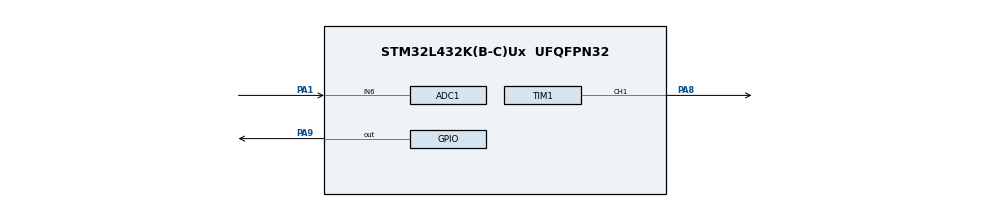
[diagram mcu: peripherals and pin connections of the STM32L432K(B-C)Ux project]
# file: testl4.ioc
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ADC1.Channel-0\#ChannelRegularConversion=ADC_CHANNEL_6
ADC1.ContinuousConvMode=ENABLE
ADC1.NbrOfConversionFlag=1
ADC1.OffsetNumber-0\#ChannelRegularConversion=ADC_OFFSET_NONE
ADC1.Overrun=ADC_OVR_DATA_OVERWRITTEN
ADC1.Rank-0\#ChannelRegularConversion=1
ADC1.SamplingTime-0\#ChannelRegularConversion=ADC_SAMPLETIME_2CYCLES_5
ADC1.master=1
Mcu.Family=STM32L4
Mcu.Name=STM32L432K(B-C)Ux
Mcu.Package=UFQFPN32
NVIC.ADC1_IRQn=true\:0\:0\:false\:false\:true\:true
NVIC.PriorityGroup=NVIC_PRIORITYGROUP_4
NVIC.TIM1_CC_IRQn=true\:0\:0\:false\:false\:true\:true
PA1.Signal=SharedAnalog_PA1
PA8.GPIO_Speed=GPIO_SPEED_FREQ_VERY_HIGH
PA8.Signal=S_TIM1_CH1
PA9.PinState=GPIO_PIN_SET
PA9.Signal=GPIO_Output
ProjectManager.HeapSize=0x200
ProjectManager.StackSize=0x400
ProjectManager.TargetToolchain=SW4STM32
RCC.ADCFreq_Value=32000000
RCC.HSE_VALUE=8000000
RCC.HSI48_VALUE=48000000
RCC.HSI_VALUE=16000000
RCC.LSE_VALUE=32768
RCC.MSI_VALUE=4000000
RCC.PLLSAI1N=16
RCC.USBFreq_Value=32000000
RCC.VCOOutputFreq_Value=32000000
SH.S_TIM1_CH1.0=TIM1_CH1,PWM Generation1 CH1
SH.SharedAnalog_PA1.0=COMP1_INP
SH.SharedAnalog_PA1.1=ADC1_IN6,IN6-Single-Ended
TIM1.AutoReloadPreload=TIM_AUTORELOAD_PRELOAD_ENABLE
TIM1.Channel-PWM\ Generation1\ CH1=TIM_CHANNEL_1
TIM1.OCMode_PWM-PWM\ Generation1\ CH1=TIM_OCMODE_PWM2
TIM1.Period=100
TIM1.Prescaler=40
TIM1.Pulse-PWM\ Generation1\ CH1=50
VP_TIM1_VS_ClockSourceINT.Mode=Internal
board=testl4

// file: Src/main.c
/**
  ******************************************************************************
  * File Name          : main.c
  * Description        : Main program body
  ******************************************************************************
  ** This notice applies to any and all portions of this file
  * that are not between comment pairs USER CODE BEGIN and
  * USER CODE END. Other portions of this file, whether
  * inserted by the user or by software development tools
  * are owned by their respective copyright owners.
  *
  * COPYRIGHT(c) 2017 STMicroelectronics
  *
  * Redistribution and use in source and binary forms, with or without modification,
  * are permitted provided that the following conditions are met:
  *   1. Redistributions of source code must retain the above copyright notice,
  *      this list of conditions and the following disclaimer.
  *   2. Redistributions in binary form must reproduce the above copyright notice,
  *      this list of conditions and the following disclaimer in the documentation
  *      and/or other materials provided with the distribution.
  *   3. Neither the name of STMicroelectronics nor the names of its contributors
  *      may be used to endorse or promote products derived from this software
  *      without specific prior written permission.
  *
  * THIS SOFTWARE IS PROVIDED BY THE COPYRIGHT HOLDERS AND CONTRIBUTORS "AS IS"
  * AND ANY EXPRESS OR IMPLIED WARRANTIES, INCLUDING, BUT NOT LIMITED TO, THE
  * IMPLIED WARRANTIES OF MERCHANTABILITY AND FITNESS FOR A PARTICULAR PURPOSE ARE
  * DISCLAIMED. IN NO EVENT SHALL THE COPYRIGHT HOLDER OR CONTRIBUTORS BE LIABLE
  * FOR ANY DIRECT, INDIRECT, INCIDENTAL, SPECIAL, EXEMPLARY, OR CONSEQUENTIAL
  * DAMAGES (INCLUDING, BUT NOT LIMITED TO, PROCUREMENT OF SUBSTITUTE GOODS OR
  * SERVICES; LOSS OF USE, DATA, OR PROFITS; OR BUSINESS INTERRUPTION) HOWEVER
  * CAUSED AND ON ANY THEORY OF LIABILITY, WHETHER IN CONTRACT, STRICT LIABILITY,
  * OR TORT (INCLUDING NEGLIGENCE OR OTHERWISE) ARISING IN ANY WAY OUT OF THE USE
  * OF THIS SOFTWARE, EVEN IF ADVISED OF THE POSSIBILITY OF SUCH DAMAGE.
  *
  ******************************************************************************
  */
#include "main.h"
#include "stm32l4xx_hal.h"

ADC_HandleTypeDef hadc1;

TIM_HandleTypeDef htim1;

/* USER CODE BEGIN PV */
/* Private variables ---------------------------------------------------------*/

/* USER CODE END PV */

void SystemClock_Config(void);
static void MX_GPIO_Init(void);
static void MX_TIM1_Init(void);
static void MX_ADC1_Init(void);

void HAL_TIM_MspPostInit(TIM_HandleTypeDef *htim);

/* USER CODE BEGIN PFP */
/* Private function prototypes -----------------------------------------------*/

/* USER CODE END PFP */

int main(void)
{

  /* MCU Configuration----------------------------------------------------------*/

  /* Reset of all peripherals, Initializes the Flash interface and the Systick. */
  HAL_Init();

  /* Configure the system clock */
  SystemClock_Config();

  /* USER CODE BEGIN SysInit */
  uint8_t egr_val;
  /* USER CODE END SysInit */

  /* Initialize all configured peripherals */
  MX_GPIO_Init();
  MX_TIM1_Init();
  MX_ADC1_Init();

  /* USER CODE BEGIN 2 */
  //HAL_ADC_Start_IT(&hadc1);
  HAL_TIM_PWM_Start(&htim1,TIM_CHANNEL_1);
  //HAL_TIM_PWM_Start(&htim1,TIM_CHANNEL_2);
  int i = 0;
  /* USER CODE END 2 */

  /* Infinite loop */
  /* USER CODE BEGIN WHILE */
  while (1)
  {
	  //egr_val = *egr;
	  printf("egr: ");
  /* USER CODE END WHILE */

  }

}

/** System Clock Configuration
*/
void SystemClock_Config(void)
{

  RCC_OscInitTypeDef RCC_OscInitStruct;
  RCC_ClkInitTypeDef RCC_ClkInitStruct;
  RCC_PeriphCLKInitTypeDef PeriphClkInit;

    /**Initializes the CPU, AHB and APB busses clocks
    */
  RCC_OscInitStruct.OscillatorType = RCC_OSCILLATORTYPE_MSI;
  RCC_OscInitStruct.MSIState = RCC_MSI_ON;
  RCC_OscInitStruct.MSICalibrationValue = 0;
  RCC_OscInitStruct.MSIClockRange = RCC_MSIRANGE_6;
  RCC_OscInitStruct.PLL.PLLState = RCC_PLL_NONE;
  if (HAL_RCC_OscConfig(&RCC_OscInitStruct) != HAL_OK)
  {
    _Error_Handler(__FILE__, __LINE__);
  }

    /**Initializes the CPU, AHB and APB busses clocks
    */
  RCC_ClkInitStruct.ClockType = RCC_CLOCKTYPE_HCLK|RCC_CLOCKTYPE_SYSCLK
                              |RCC_CLOCKTYPE_PCLK1|RCC_CLOCKTYPE_PCLK2;
  RCC_ClkInitStruct.SYSCLKSource = RCC_SYSCLKSOURCE_MSI;
  RCC_ClkInitStruct.AHBCLKDivider = RCC_SYSCLK_DIV1;
  RCC_ClkInitStruct.APB1CLKDivider = RCC_HCLK_DIV1;
  RCC_ClkInitStruct.APB2CLKDivider = RCC_HCLK_DIV1;

  if (HAL_RCC_ClockConfig(&RCC_ClkInitStruct, FLASH_LATENCY_0) != HAL_OK)
  {
    _Error_Handler(__FILE__, __LINE__);
  }

  PeriphClkInit.PeriphClockSelection = RCC_PERIPHCLK_ADC;
  PeriphClkInit.AdcClockSelection = RCC_ADCCLKSOURCE_PLLSAI1;
  PeriphClkInit.PLLSAI1.PLLSAI1Source = RCC_PLLSOURCE_MSI;
  PeriphClkInit.PLLSAI1.PLLSAI1M = 1;
  PeriphClkInit.PLLSAI1.PLLSAI1N = 16;
  PeriphClkInit.PLLSAI1.PLLSAI1P = RCC_PLLP_DIV7;
  PeriphClkInit.PLLSAI1.PLLSAI1Q = RCC_PLLQ_DIV2;
  PeriphClkInit.PLLSAI1.PLLSAI1R = RCC_PLLR_DIV2;
  PeriphClkInit.PLLSAI1.PLLSAI1ClockOut = RCC_PLLSAI1_ADC1CLK;
  if (HAL_RCCEx_PeriphCLKConfig(&PeriphClkInit) != HAL_OK)
  {
    _Error_Handler(__FILE__, __LINE__);
  }

    /**Configure the main internal regulator output voltage
    */
  if (HAL_PWREx_ControlVoltageScaling(PWR_REGULATOR_VOLTAGE_SCALE1) != HAL_OK)
  {
    _Error_Handler(__FILE__, __LINE__);
  }

    /**Configure the Systick interrupt time
    */
  HAL_SYSTICK_Config(HAL_RCC_GetHCLKFreq()/1000);

    /**Configure the Systick
    */
  HAL_SYSTICK_CLKSourceConfig(SYSTICK_CLKSOURCE_HCLK);

  /* SysTick_IRQn interrupt configuration */
  HAL_NVIC_SetPriority(SysTick_IRQn, 0, 0);
}

/* ADC1 init function */
static void MX_ADC1_Init(void)
{

  ADC_ChannelConfTypeDef sConfig;

    /**Common config
    */
  hadc1.Instance = ADC1;
  hadc1.Init.ClockPrescaler = ADC_CLOCK_ASYNC_DIV1;
  hadc1.Init.Resolution = ADC_RESOLUTION_12B;
  hadc1.Init.DataAlign = ADC_DATAALIGN_RIGHT;
  hadc1.Init.ScanConvMode = ADC_SCAN_DISABLE;
  hadc1.Init.EOCSelection = ADC_EOC_SINGLE_CONV;
  hadc1.Init.LowPowerAutoWait = DISABLE;
  hadc1.Init.ContinuousConvMode = ENABLE;
  hadc1.Init.NbrOfConversion = 1;
  hadc1.Init.DiscontinuousConvMode = DISABLE;
  hadc1.Init.NbrOfDiscConversion = 1;
  hadc1.Init.ExternalTrigConv = ADC_SOFTWARE_START;
  hadc1.Init.ExternalTrigConvEdge = ADC_EXTERNALTRIGCONVEDGE_NONE;
  hadc1.Init.DMAContinuousRequests = DISABLE;
  hadc1.Init.Overrun = ADC_OVR_DATA_OVERWRITTEN;
  hadc1.Init.OversamplingMode = DISABLE;
  if (HAL_ADC_Init(&hadc1) != HAL_OK)
  {
    _Error_Handler(__FILE__, __LINE__);
  }

    /**Configure Regular Channel
    */
  sConfig.Channel = ADC_CHANNEL_6;
  sConfig.Rank = 1;
  sConfig.SamplingTime = ADC_SAMPLETIME_2CYCLES_5;
  sConfig.SingleDiff = ADC_SINGLE_ENDED;
  sConfig.OffsetNumber = ADC_OFFSET_NONE;
  sConfig.Offset = 0;
  if (HAL_ADC_ConfigChannel(&hadc1, &sConfig) != HAL_OK)
  {
    _Error_Handler(__FILE__, __LINE__);
  }

}

/* TIM1 init function */
static void MX_TIM1_Init(void)
{

  TIM_ClockConfigTypeDef sClockSourceConfig;
  TIM_MasterConfigTypeDef sMasterConfig;
  TIM_OC_InitTypeDef sConfigOC;
  TIM_BreakDeadTimeConfigTypeDef sBreakDeadTimeConfig;

  htim1.Instance = TIM1;
  htim1.Init.Prescaler = 40;
  htim1.Init.CounterMode = TIM_COUNTERMODE_UP;
  htim1.Init.Period = 100;
  htim1.Init.ClockDivision = TIM_CLOCKDIVISION_DIV1;
  htim1.Init.RepetitionCounter = 0;
  htim1.Init.AutoReloadPreload = TIM_AUTORELOAD_PRELOAD_ENABLE;
  if (HAL_TIM_Base_Init(&htim1) != HAL_OK)
  {
    _Error_Handler(__FILE__, __LINE__);
  }

  sClockSourceConfig.ClockSource = TIM_CLOCKSOURCE_INTERNAL;
  if (HAL_TIM_ConfigClockSource(&htim1, &sClockSourceConfig) != HAL_OK)
  {
    _Error_Handler(__FILE__, __LINE__);
  }

  if (HAL_TIM_PWM_Init(&htim1) != HAL_OK)
  {
    _Error_Handler(__FILE__, __LINE__);
  }

  sMasterConfig.MasterOutputTrigger = TIM_TRGO_RESET;
  sMasterConfig.MasterOutputTrigger2 = TIM_TRGO2_RESET;
  sMasterConfig.MasterSlaveMode = TIM_MASTERSLAVEMODE_DISABLE;
  if (HAL_TIMEx_MasterConfigSynchronization(&htim1, &sMasterConfig) != HAL_OK)
  {
    _Error_Handler(__FILE__, __LINE__);
  }

  sConfigOC.OCMode = TIM_OCMODE_PWM2;
  sConfigOC.Pulse = 50;
  sConfigOC.OCPolarity = TIM_OCPOLARITY_HIGH;
  sConfigOC.OCNPolarity = TIM_OCNPOLARITY_HIGH;
  sConfigOC.OCFastMode = TIM_OCFAST_DISABLE;
  sConfigOC.OCIdleState = TIM_OCIDLESTATE_RESET;
  sConfigOC.OCNIdleState = TIM_OCNIDLESTATE_RESET;
  if (HAL_TIM_PWM_ConfigChannel(&htim1, &sConfigOC, TIM_CHANNEL_1) != HAL_OK)
  {
    _Error_Handler(__FILE__, __LINE__);
  }

  sBreakDeadTimeConfig.OffStateRunMode = TIM_OSSR_DISABLE;
  sBreakDeadTimeConfig.OffStateIDLEMode = TIM_OSSI_DISABLE;
  sBreakDeadTimeConfig.LockLevel = TIM_LOCKLEVEL_OFF;
  sBreakDeadTimeConfig.DeadTime = 0;
  sBreakDeadTimeConfig.BreakState = TIM_BREAK_DISABLE;
  sBreakDeadTimeConfig.BreakPolarity = TIM_BREAKPOLARITY_HIGH;
  sBreakDeadTimeConfig.BreakFilter = 0;
  sBreakDeadTimeConfig.Break2State = TIM_BREAK2_DISABLE;
  sBreakDeadTimeConfig.Break2Polarity = TIM_BREAK2POLARITY_HIGH;
  sBreakDeadTimeConfig.Break2Filter = 0;
  sBreakDeadTimeConfig.AutomaticOutput = TIM_AUTOMATICOUTPUT_DISABLE;
  if (HAL_TIMEx_ConfigBreakDeadTime(&htim1, &sBreakDeadTimeConfig) != HAL_OK)
  {
    _Error_Handler(__FILE__, __LINE__);
  }

  HAL_TIM_MspPostInit(&htim1);

}

/** Configure pins
     PA1   ------> SharedAnalog_PA1
*/
static void MX_GPIO_Init(void)
{

  GPIO_InitTypeDef GPIO_InitStruct;

  /* GPIO Ports Clock Enable */
  __HAL_RCC_GPIOA_CLK_ENABLE();

  /*Configure GPIO pin Output Level */
  HAL_GPIO_WritePin(GPIOA, GPIO_PIN_9, GPIO_PIN_SET);

  /*Configure GPIO pin : PA1 */
  GPIO_InitStruct.Pin = GPIO_PIN_1;
  GPIO_InitStruct.Mode = GPIO_MODE_ANALOG;
  GPIO_InitStruct.Pull = GPIO_NOPULL;
  HAL_GPIO_Init(GPIOA, &GPIO_InitStruct);

  /*Configure GPIO pin : PA9 */
  GPIO_InitStruct.Pin = GPIO_PIN_9;
  GPIO_InitStruct.Mode = GPIO_MODE_OUTPUT_PP;
  GPIO_InitStruct.Pull = GPIO_NOPULL;
  GPIO_InitStruct.Speed = GPIO_SPEED_FREQ_LOW;
  HAL_GPIO_Init(GPIOA, &GPIO_InitStruct);

}

void _Error_Handler(char * file, int line)
{
  while(1)
  {
  }
}

/************************ (C) COPYRIGHT STMicroelectronics *****END OF FILE****/
